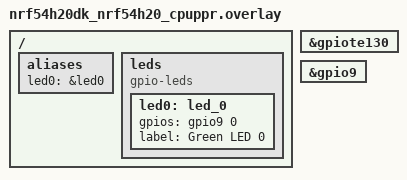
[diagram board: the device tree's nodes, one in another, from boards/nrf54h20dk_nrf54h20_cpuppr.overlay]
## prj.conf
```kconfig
#CONFIG_GPIO=y
# Logging
CONFIG_LOG=y
CONFIG_PRINTK=y
CONFIG_CONSOLE=y
CONFIG_UART_CONSOLE=y

# I2C Support
CONFIG_I2C=y

# GPIO Support
CONFIG_GPIO=y

# Increase stack size for main thread
CONFIG_MAIN_STACK_SIZE=2048
```

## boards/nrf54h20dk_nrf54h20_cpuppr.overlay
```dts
/* SPDX-License-Identifier: Apache-2.0 */

/ {
	aliases {
		led0 = &led0;
	};

	leds {
		compatible = "gpio-leds";
		led0: led_0 {
			gpios = <&gpio9 0 GPIO_ACTIVE_HIGH>;
			label = "Green LED 0";
		};
	};
};

&gpiote130 {
	status = "okay";
};

&gpio9 {
	status = "okay";
};
```

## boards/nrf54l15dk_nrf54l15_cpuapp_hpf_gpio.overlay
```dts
/*
 * Copyright (c) 2024 Nordic Semiconductor ASA
 *
 * SPDX-License-Identifier: LicenseRef-Nordic-5-Clause
 */

&led0 {
	gpios = <&hpf_gpio 9 GPIO_ACTIVE_HIGH>;
};
```

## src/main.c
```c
#include "C:\Users\srish\OneDrive\Desktop\hackathon\blinky\src\sensors\max30102.c"
#include "C:\Users\srish\OneDrive\Desktop\hackathon\blinky\src\sensors\mpu6050.c"



int main(void)
{
    mpu6050();
    max_30102();
    return 0;

}
```
